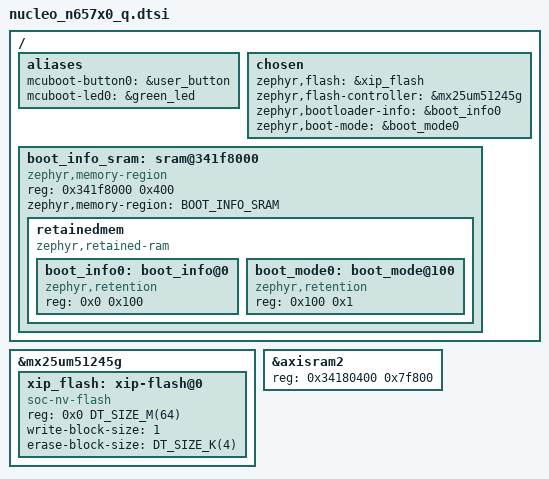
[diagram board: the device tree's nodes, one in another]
/* Delete Zephyr-default partitions before redefining them. */
&mx25um51245g { /delete-node/ partitions; };

/* XIP code flash: the N6 has no internal flash, so code-partition images
 * execute in place from the XSPI NOR's memory-mapped window. Mirror the
 * upstream stm32n6570_dk pattern: a soc-nv-flash child of the XSPI NOR node,
 * with ranges translating the child's offsets into the memory-mapped base
 * (xspi2 -> 0x70000000). The partitions dtsi (generated, included below) hangs
 * the partition layout off this node; the runtime flash driver is still the
 * parent st,stm32-xspi-nor (flash_map walks up the parent chain to find it).
 * The node must be defined before the include: label references in the
 * devicetree are resolved in document order.
 */
&mx25um51245g {
	#address-cells = <1>;
	#size-cells = <1>;
	ranges = <0x0 0x70000000 DT_SIZE_M(64)>; /* 512 Mbits */

	xip_flash: xip-flash@0 {
		compatible = "soc-nv-flash";
		reg = <0x0 DT_SIZE_M(64)>;
		write-block-size = <1>;
		erase-block-size = <DT_SIZE_K(4)>;

		/* Map the flash's child address space into the CPU's memory-mapped
		 * window so the mapped-partition reg addresses resolve absolutely
		 * (the partitions node included below only carries an empty
		 * `ranges;`, and an NVM memory node must carry its own ranges per
		 * the zephyr,mapped-partition binding). Without this, the linker's
		 * ROM_ADDR (DT_REG_ADDR of the chosen code partition) and mcuboot's
		 * XIP jump disagree with where the code actually executes.
		 */
		#address-cells = <1>;
		#size-cells = <1>;
		ranges = <0x0 0x70000000 DT_SIZE_M(64)>;
	};
};

/* The fork's generated partitions dtsi (included below) must be
 * self-contained, so the delete applies to the device the layout hangs off
 * as well: without it the planner treats its own previous output as an
 * upstream predefined layout and skips re-emitting the boot/slot partitions.
 */
&xip_flash { /delete-node/ partitions; };

/ {
	aliases {
		mcuboot-button0 = &user_button;
		mcuboot-led0 = &green_led;
	};
};

#include "nucleo_n657x0_q-partitions.dtsi"

/* Flash chosen properties needed by both builds:
 * - zephyr,flash = the XIP flash: the STM32 soc layer derives the linker's
 *   flash base from its parent (0 for the XSPI NOR) and code-partition images
 *   link at their memory-mapped addresses; the imgtool signing step
 *   (deps/zephyr/cmake/mcuboot.cmake) also reads write-block-size from it.
 * - zephyr,flash-controller mirrors upstream (the XSPI NOR device node).
 * zephyr,code-partition is deliberately not set here -- boot/zephyr/app.overlay
 * points it at boot_partition for the bootloader and
 * samples/bootloader-updater/app.overlay at slot0 for the updater, and this
 * overlay is applied after those.
 */
/ {
	chosen {
		zephyr,flash = &xip_flash;
		zephyr,flash-controller = &mx25um51245g;
	};
};
/* Bootloader info shared-data area: the last KB of this board's RAM, kept
 * out of the managed RAM so neither image clobbers it. The bootloader
 * writes its boot state here on every boot (BOOT_SHARE_DATA_BOOTINFO ->
 * BLINFO TLVs via boot_write_shared_data()); the application reads the
 * same region to answer the SMP bootloader-info command (RETENTION_
 * BOOTLOADER_INFO_TYPE_MCUBOOT). Carved here because this dtsi applies to
 * both images.
 *
 * A second, one-byte retention cell in the same block backs the boot-mode
 * flag (zephyr,boot-mode): the application sets it to request the
 * bootloader's update mode (reset_to_bootloader() / RunMode.UF2) and the
 * bootloader reads and clears it at boot (io_detect_boot_mode()). SRAM
 * content survives the warm reset that follows the request, which is all a
 * button-less entrance needs; a power cycle simply drops the request.
 */
&axisram2 {
	reg = <0x34180400 0x7f800>;
};

/ {
	chosen {
		zephyr,bootloader-info = &boot_info0;
		zephyr,boot-mode = &boot_mode0;
	};

	boot_info_sram: sram@341f8000 {
		compatible = "zephyr,memory-region", "mmio-sram";
		reg = <0x341f8000 0x400>;
		zephyr,memory-region = "BOOT_INFO_SRAM";
		status = "okay";

		retainedmem {
			compatible = "zephyr,retained-ram";
			status = "okay";
			#address-cells = <1>;
			#size-cells = <1>;

			boot_info0: boot_info@0 {
				compatible = "zephyr,retention";
				status = "okay";
				reg = <0x0 0x100>;
			};

			boot_mode0: boot_mode@100 {
				compatible = "zephyr,retention";
				status = "okay";
				reg = <0x100 0x1>;
			};
		};
	};
};
